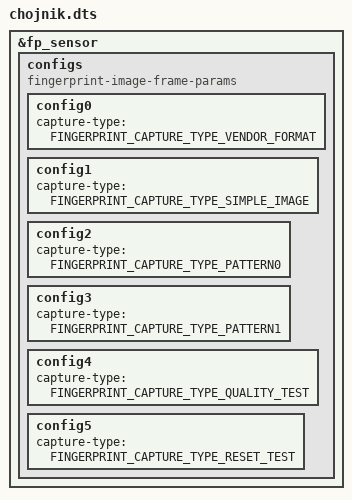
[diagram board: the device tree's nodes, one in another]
/* Copyright 2025 The ChromiumOS Authors.
 * Use of this source code is governed by a BSD-style license that can be
 * found in the LICENSE file.
 */

#include "common.dtsi"

#define FT9865_COMMON_IMAGE_PROPS \
	width = <64>; \
	height = <80>; \
	bits-per-pixel = <8>; \
	frame-size = <5120>; \
	v4l2-pixel-format = "V4L2_PIX_FMT_GREY";

&fp_sensor {
	configs {
		compatible = "fingerprint-image-frame-params";
		config0 {
			FT9865_COMMON_IMAGE_PROPS
			capture-type = "FINGERPRINT_CAPTURE_TYPE_VENDOR_FORMAT";
		};
		config1 {
			FT9865_COMMON_IMAGE_PROPS
			capture-type = "FINGERPRINT_CAPTURE_TYPE_SIMPLE_IMAGE";
		};
		config2 {
			FT9865_COMMON_IMAGE_PROPS
			capture-type = "FINGERPRINT_CAPTURE_TYPE_PATTERN0";
		};
		config3 {
			FT9865_COMMON_IMAGE_PROPS
			capture-type = "FINGERPRINT_CAPTURE_TYPE_PATTERN1";
		};
		config4 {
			FT9865_COMMON_IMAGE_PROPS
			capture-type = "FINGERPRINT_CAPTURE_TYPE_QUALITY_TEST";
		};
		config5 {
			FT9865_COMMON_IMAGE_PROPS
			capture-type = "FINGERPRINT_CAPTURE_TYPE_RESET_TEST";
		};
	};
};
